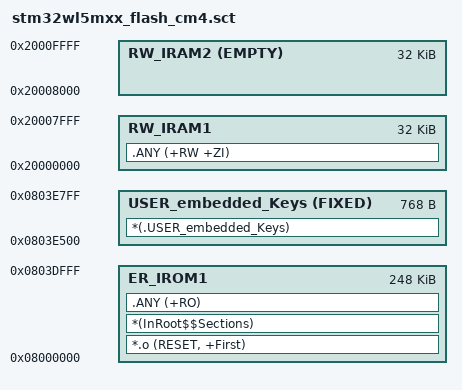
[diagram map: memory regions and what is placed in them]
; *************************************************************
; *** Scatter-Loading Description File generated by uVision ***
; *************************************************************

LR_IROM1 0x08000000 0x0003E000  {    ; load region size_region
  ; FLASH
  ER_IROM1 0x08000000 0x0003E000  {  ; load address = execution address
   *.o (RESET, +First)
   *(InRoot$$Sections)
   .ANY (+RO)
  }
  ; Non-backup SRAM1
  RW_IRAM1 0x20000000 0x00008000  {  ; RW data
   .ANY (+RW +ZI)
  }
  ; Backup SRAM2
  RW_IRAM2 0x20008000 EMPTY 0x00008000  {  ; to be modified accordingly to user project. Can be NoInit data for backup usage, RW, ZI region, etc...
  }
}

LR_IROM2 0x0803E500 0x00000300  {    ; load region size_region
  ;SE Embedded Keys
  USER_embedded_Keys 0x0803E500 FIXED 0x300 {
    *(.USER_embedded_Keys)
  }
}
